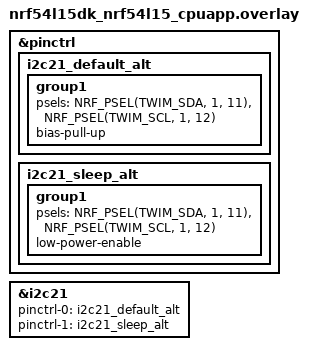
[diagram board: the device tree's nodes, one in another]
/*
 * Copyright (c) 2025 Nordic Semiconductor ASA
 *
 * SPDX-License-Identifier: LicenseRef-Nordic-5-Clause
 */

&pinctrl {
	i2c21_default_alt: i2c21_default_alt {
		group1 {
			psels = <NRF_PSEL(TWIM_SDA, 1, 11)>,
				<NRF_PSEL(TWIM_SCL, 1, 12)>;
			bias-pull-up;
		};
	};

	i2c21_sleep_alt: i2c21_sleep_alt {
		group1 {
			psels = <NRF_PSEL(TWIM_SDA, 1, 11)>,
				<NRF_PSEL(TWIM_SCL, 1, 12)>;
			low-power-enable;
		};
	};
};

&i2c21 {
	status = "okay";
	pinctrl-0 = <&i2c21_default_alt>;
	pinctrl-1 = <&i2c21_sleep_alt>;
	pinctrl-names = "default", "sleep";

	#include "npm2100ek_pmic.dtsi"
};
